VERSION ""

NS_ :

BS_:

BU_: BMS_MASTER STEALTHEV_CHARGER BMS_SLAVE1 BMS_SLAVE2 BMS_SLAVE3

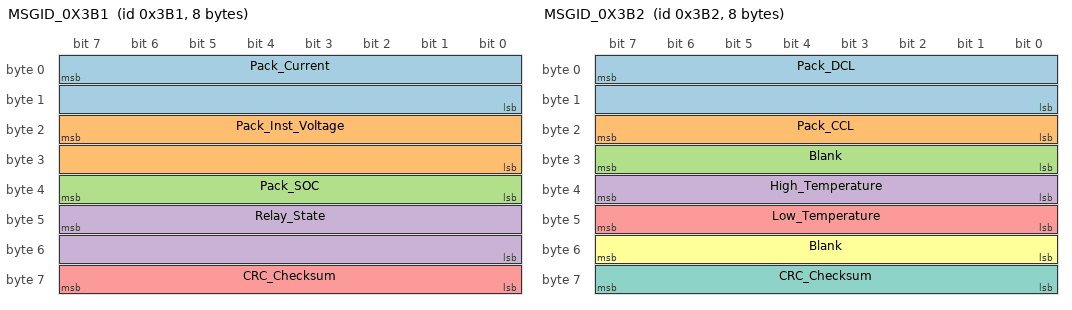
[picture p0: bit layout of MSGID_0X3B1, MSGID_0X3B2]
BO_ 945 MSGID_0X3B1: 8 BMS_MASTER
 SG_ Pack_Current : 7|16@0+ (0.1,0) [0|0] "Amps"  STEALTHEV_CHARGER
 SG_ Pack_Inst_Voltage : 23|16@0+ (0.1,0) [0|0] "Volts"  STEALTHEV_CHARGER
 SG_ Pack_SOC : 39|8@0+ (0.5,0) [0|0] "Percent"  STEALTHEV_CHARGER
 SG_ Relay_State : 47|16@0+ (1,0) [0|0] ""  STEALTHEV_CHARGER
 SG_ CRC_Checksum : 63|8@0+ (1,1720) [0|0] ""  STEALTHEV_CHARGER

BO_ 946 MSGID_0X3B2: 8 BMS_MASTER
 SG_ Pack_DCL : 7|16@0+ (1,0) [0|0] "Amps"  STEALTHEV_CHARGER
 SG_ Pack_CCL : 23|8@0+ (1,0) [0|0] "Amps"  STEALTHEV_CHARGER
 SG_ Blank : 31|8@0+ (1,0) [0|0] ""  STEALTHEV_CHARGER
 SG_ High_Temperature : 39|8@0+ (1,0) [0|0] "Celsius"  STEALTHEV_CHARGER
 SG_ Low_Temperature : 47|8@0+ (1,0) [0|0] "Celsius"  STEALTHEV_CHARGER
 SG_ Blank : 55|8@0+ (1,0) [0|0] ""  STEALTHEV_CHARGER
 SG_ CRC_Checksum : 63|8@0+ (1,1721) [0|0] ""  STEALTHEV_CHARGER

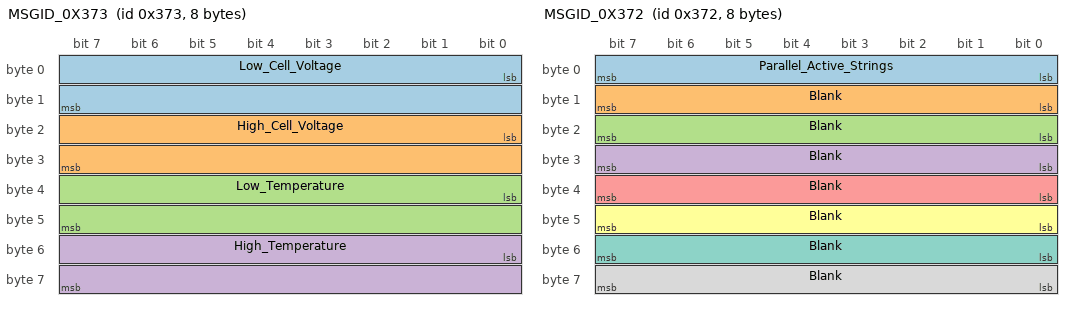
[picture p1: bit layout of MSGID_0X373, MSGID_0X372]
BO_ 883 MSGID_0X373: 8 BMS_MASTER
 SG_ Low_Cell_Voltage : 0|16@1+ (0.001,0) [0|0] "Volts"  STEALTHEV_CHARGER
 SG_ High_Cell_Voltage : 16|16@1+ (0.001,0) [0|0] "Volts"  STEALTHEV_CHARGER
 SG_ Low_Temperature : 32|16@1+ (1,273) [0|0] "Celsius"  STEALTHEV_CHARGER
 SG_ High_Temperature : 48|16@1+ (1,273) [0|0] "Celsius"  STEALTHEV_CHARGER

BO_ 882 MSGID_0X372: 8 BMS_MASTER
 SG_ Parallel_Active_Strings : 0|8@1+ (1,0) [0|0] "Num"  STEALTHEV_CHARGER
 SG_ Blank : 8|8@1+ (1,0) [0|0] ""  STEALTHEV_CHARGER
 SG_ Blank : 16|8@1+ (1,273) [0|0] ""  STEALTHEV_CHARGER
 SG_ Blank : 24|8@1+ (1,0) [0|0] ""  STEALTHEV_CHARGER
 SG_ Blank : 32|8@1+ (10,0) [0|0] ""  STEALTHEV_CHARGER
 SG_ Blank : 40|8@1+ (1,0) [0|0] ""  STEALTHEV_CHARGER
 SG_ Blank : 55|8@0+ (1,0) [0|0] ""  STEALTHEV_CHARGER
 SG_ Blank : 63|8@0+ (1,0) [0|0] ""  STEALTHEV_CHARGER

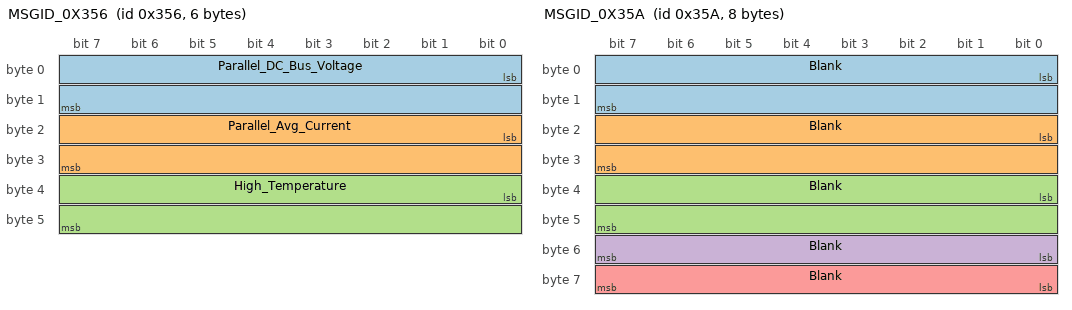
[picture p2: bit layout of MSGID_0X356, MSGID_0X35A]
BO_ 854 MSGID_0X356: 6 BMS_MASTER
 SG_ Parallel_DC_Bus_Voltage : 0|16@1+ (0.01,0) [0|0] "Volts"  STEALTHEV_CHARGER
 SG_ Parallel_Avg_Current : 16|16@1- (1.5259021897e-06,0) [0|0] "Amps"  STEALTHEV_CHARGER
 SG_ High_Temperature : 32|16@1+ (0.1,0) [0|0] "Celsius"  STEALTHEV_CHARGER

BO_ 858 MSGID_0X35A: 8 BMS_MASTER
 SG_ Blank : 0|16@1+ (1,0) [0|0] ""  STEALTHEV_CHARGER
 SG_ Blank : 16|16@1+ (1,0) [0|0] ""  STEALTHEV_CHARGER
 SG_ Blank : 32|16@1+ (1,0) [0|0] ""  STEALTHEV_CHARGER
 SG_ Blank : 55|8@0+ (1,0) [0|0] ""  STEALTHEV_CHARGER
 SG_ Blank : 63|8@0+ (1,0) [0|0] ""  STEALTHEV_CHARGER

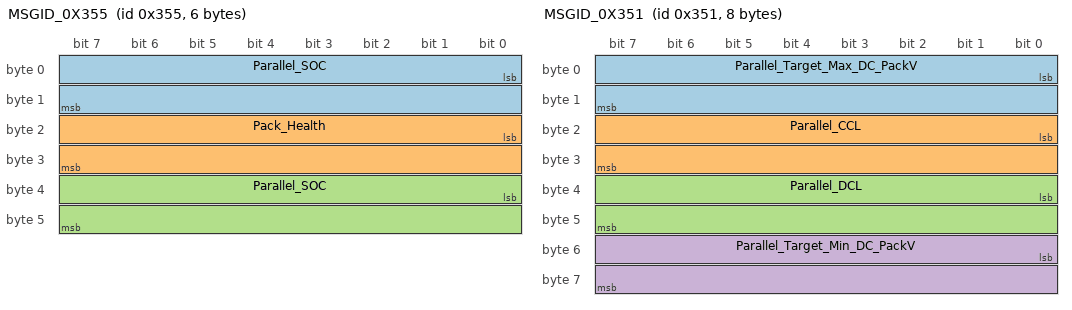
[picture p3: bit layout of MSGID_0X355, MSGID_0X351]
BO_ 853 MSGID_0X355: 6 BMS_MASTER
 SG_ Parallel_SOC : 0|16@1+ (1,0) [0|0] "Percent"  STEALTHEV_CHARGER
 SG_ Pack_Health : 16|16@1+ (1,0) [0|0] "Percent"  STEALTHEV_CHARGER
 SG_ Parallel_SOC : 32|16@1+ (0.1,0) [0|0] "Percent"  STEALTHEV_CHARGER

BO_ 849 MSGID_0X351: 8 BMS_MASTER
 SG_ Parallel_Target_Max_DC_PackV : 0|16@1+ (0.1,0) [0|0] "Volts"  STEALTHEV_CHARGER
 SG_ Parallel_CCL : 16|16@1+ (0.1,0) [0|0] "Amps"  STEALTHEV_CHARGER
 SG_ Parallel_DCL : 32|16@1+ (0.1,0) [0|0] "Amps"  STEALTHEV_CHARGER
 SG_ Parallel_Target_Min_DC_PackV : 48|16@1+ (0.1,0) [0|0] "Volts"  STEALTHEV_CHARGER

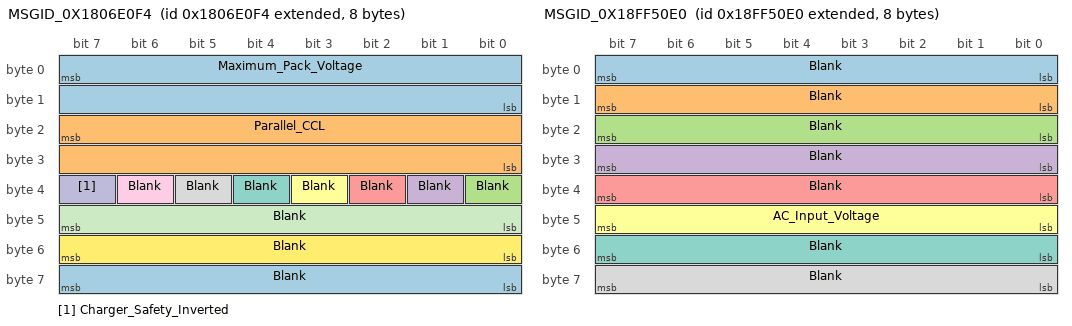
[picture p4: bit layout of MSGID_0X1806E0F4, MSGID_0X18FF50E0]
BO_ 2550587636 MSGID_0X1806E0F4: 8 BMS_MASTER
 SG_ Maximum_Pack_Voltage : 7|16@0+ (0.1,0) [0|0] "Volts"  STEALTHEV_CHARGER
 SG_ Parallel_CCL : 23|16@0+ (0.1,0) [0|0] "Amps"  STEALTHEV_CHARGER
 SG_ Blank : 32|1@1+ (1,0) [0|1] ""  STEALTHEV_CHARGER
 SG_ Blank : 33|1@1+ (1,0) [0|1] ""  STEALTHEV_CHARGER
 SG_ Blank : 34|1@1+ (1,0) [0|1] ""  STEALTHEV_CHARGER
 SG_ Blank : 35|1@1+ (1,0) [0|1] ""  STEALTHEV_CHARGER
 SG_ Blank : 36|1@1+ (1,0) [0|1] ""  STEALTHEV_CHARGER
 SG_ Blank : 37|1@1+ (1,0) [0|1] ""  STEALTHEV_CHARGER
 SG_ Blank : 38|1@1+ (1,0) [0|1] ""  STEALTHEV_CHARGER
 SG_ Charger_Safety_Inverted : 39|1@1+ (1,0) [0|1] ""  STEALTHEV_CHARGER
 SG_ Blank : 47|8@0+ (1,0) [0|0] ""  STEALTHEV_CHARGER
 SG_ Blank : 55|8@0+ (1,0) [0|0] ""  STEALTHEV_CHARGER
 SG_ Blank : 63|8@0+ (1,0) [0|0] ""  STEALTHEV_CHARGER

BO_ 2566869216 MSGID_0X18FF50E0: 8 STEALTHEV_CHARGER
 SG_ Blank : 7|8@0+ (1,0) [0|0] ""  BMS_MASTER
 SG_ Blank : 15|8@0+ (1,0) [0|0] ""  BMS_MASTER
 SG_ Blank : 23|8@0+ (1,0) [0|0] ""  BMS_MASTER
 SG_ Blank : 31|8@0+ (1,0) [0|0] ""  BMS_MASTER
 SG_ Blank : 39|8@0+ (1,0) [0|0] ""  BMS_MASTER
 SG_ AC_Input_Voltage : 47|8@0+ (10,0) [0|0] ""  BMS_MASTER
 SG_ Blank : 55|8@0+ (1,0) [0|0] ""  BMS_MASTER
 SG_ Blank : 63|8@0+ (1,0) [0|0] ""  BMS_MASTER

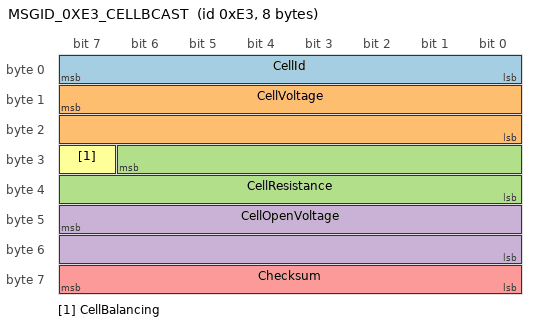
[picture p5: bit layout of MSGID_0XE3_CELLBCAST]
BO_ 227 MSGID_0XE3_CELLBCAST: 8 BMS_MASTER
 SG_ CellId : 7|8@0+ (1,0) [0|0] "#"  STEALTHEV_CHARGER
 SG_ CellVoltage : 15|16@0+ (0.0001,0) [0|0] "Volts"  STEALTHEV_CHARGER
 SG_ CellResistance : 30|15@0+ (0.01,0) [0|0] "mOhms"  STEALTHEV_CHARGER
 SG_ CellOpenVoltage : 47|16@0+ (0.0001,0) [0|0] "Volts"  STEALTHEV_CHARGER
 SG_ Checksum : 63|8@0+ (1,0) [0|0] ""  STEALTHEV_CHARGER
 SG_ CellBalancing : 31|1@1+ (1,0) [0|0] ""  STEALTHEV_CHARGER

BO_ 947 MSGID_0X3B3: 8 Vector__XXX

CM_ BO_ 945 "This ID Transmits at 104 ms.";
CM_ BO_ 946 "This ID Transmits at 104 ms.";
CM_ BO_ 883 "This ID Transmits at 104 ms.";
CM_ BO_ 882 "This ID Transmits at 104 ms.";
CM_ BO_ 854 "This ID Transmits at 104 ms.";
CM_ BO_ 858 "This ID Transmits at 104 ms.";
CM_ BO_ 853 "This ID Transmits at 104 ms.";
CM_ BO_ 849 "This ID Transmits at 104 ms.";
CM_ BO_ 2550587636 "This ID Transmits at 808 ms.";
CM_ BO_ 227 "This ID Transmits at 100 ms.";
CM_ SG_ 227 Checksum "Value = (0xE3 + 8 + byte0 + byte1 + ... + byte6) & 0xFF";
